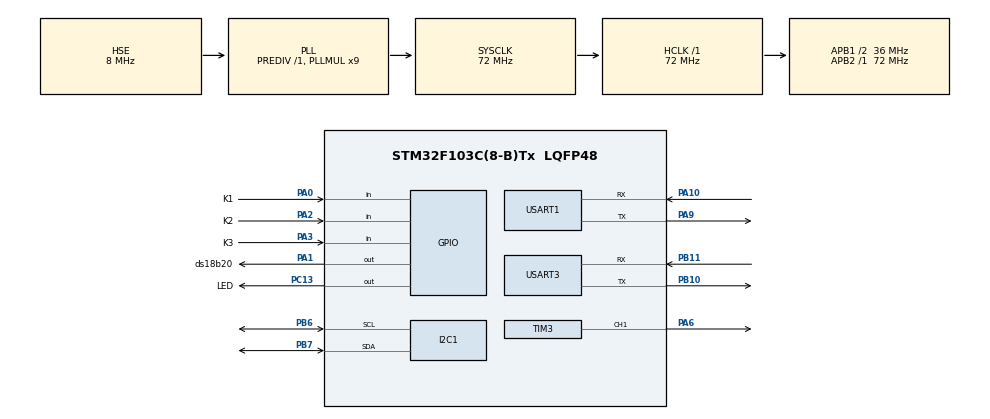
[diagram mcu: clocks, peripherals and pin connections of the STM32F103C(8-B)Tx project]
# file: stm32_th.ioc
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Mcu.Family=STM32F1
Mcu.Name=STM32F103C(8-B)Tx
Mcu.Package=LQFP48
NVIC.PriorityGroup=NVIC_PRIORITYGROUP_4
PA0-WKUP.GPIO_Label=K1
PA0-WKUP.GPIO_PuPd=GPIO_PULLUP
PA0-WKUP.Signal=GPIO_Input
PA1.GPIO_Label=ds18b20
PA1.Signal=GPIO_Output
PA10.Mode=Asynchronous
PA10.Signal=USART1_RX
PA13.Mode=Serial_Wire
PA13.Signal=SYS_JTMS-SWDIO
PA14.Mode=Serial_Wire
PA14.Signal=SYS_JTCK-SWCLK
PA2.GPIO_Label=K2
PA2.GPIO_PuPd=GPIO_PULLUP
PA2.Signal=GPIO_Input
PA3.GPIO_Label=K3
PA3.GPIO_PuPd=GPIO_PULLUP
PA3.Signal=GPIO_Input
PA6.Signal=S_TIM3_CH1
PA9.Mode=Asynchronous
PA9.Signal=USART1_TX
PB10.Mode=Asynchronous
PB10.Signal=USART3_TX
PB11.Mode=Asynchronous
PB11.Signal=USART3_RX
PB6.Mode=I2C
PB6.Signal=I2C1_SCL
PB7.Mode=I2C
PB7.Signal=I2C1_SDA
PC13-TAMPER-RTC.GPIO_Label=LED
PC13-TAMPER-RTC.Signal=GPIO_Output
PC14-OSC32_IN.Mode=LSE-External-Oscillator
PC14-OSC32_IN.Signal=RCC_OSC32_IN
PC15-OSC32_OUT.Mode=LSE-External-Oscillator
PC15-OSC32_OUT.Signal=RCC_OSC32_OUT
PD0-OSC_IN.Mode=HSE-External-Oscillator
PD0-OSC_IN.Signal=RCC_OSC_IN
PD1-OSC_OUT.Mode=HSE-External-Oscillator
PD1-OSC_OUT.Signal=RCC_OSC_OUT
ProjectManager.HeapSize=0x200
ProjectManager.StackSize=0x400
ProjectManager.TargetToolchain=STM32CubeIDE
RCC.AHBFreq_Value=72000000
RCC.APB1CLKDivider=RCC_HCLK_DIV2
RCC.APB1Freq_Value=36000000
RCC.APB1TimFreq_Value=72000000
RCC.APB2Freq_Value=72000000
RCC.APB2TimFreq_Value=72000000
RCC.HCLKFreq_Value=72000000
RCC.PLLMUL=RCC_PLL_MUL9
RCC.PLLSourceVirtual=RCC_PLLSOURCE_HSE
RCC.SYSCLKFreq_VALUE=72000000
RCC.SYSCLKSource=RCC_SYSCLKSOURCE_PLLCLK
RCC.USBFreq_Value=72000000
SH.S_TIM3_CH1.0=TIM3_CH1,PWM Generation1 CH1
TIM3.Channel-PWM\ Generation1\ CH1=TIM_CHANNEL_1
USART1.VirtualMode=VM_ASYNC
USART3.VirtualMode=VM_ASYNC
VP_TIM3_VS_ControllerModeClock.Mode=Clock Mode
board=custom

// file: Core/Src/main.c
/* USER CODE BEGIN Header */
/**
  ******************************************************************************
  * @file           : main.c
  * @brief          : Main program body
  ******************************************************************************
  * @attention
  *
  * Copyright (c) 2026 STMicroelectronics.
  * All rights reserved.
  *
  * This software is licensed under terms that can be found in the LICENSE file
  * in the root directory of this software component.
  * If no LICENSE file comes with this software, it is provided AS-IS.
  *
  ******************************************************************************
  */
/* USER CODE END Header */
#include "main.h"

/* USER CODE BEGIN Includes */
#include "scheduler.h"
#include "key.h"
#include "sensor.h"
#include "alarm.h"
#include "display.h"
#include "log.h"
#include "aht20.h"
#include "ens160.h"
/* USER CODE END Includes */

I2C_HandleTypeDef hi2c1;

TIM_HandleTypeDef htim3;

UART_HandleTypeDef huart1;
UART_HandleTypeDef huart3;

/* USER CODE BEGIN PV */
key_t g_keys[KEY_COUNT];
/* USER CODE END PV */

void SystemClock_Config(void);
static void MX_GPIO_Init(void);
static void MX_TIM3_Init(void);
static void MX_USART1_UART_Init(void);
static void MX_I2C1_Init(void);

/* USER CODE BEGIN 0 */
/* Task functions */
void Task_KeyScan(void)
{
    for (key_id_t i = 0; i < KEY_COUNT; i++) {
        Key_Scan10ms(&g_keys[i]);
        key_evt_t evt = Key_GetEvent(&g_keys[i]);
        if (evt != KEY_EVT_NONE) Menu_OnKey(i, evt);
    }
}
void Task_Display(void)
{
    sensor_data_t s = Sensor_GetData();
    Display_UpdateHistory(&s);
    Display_Refresh();
}
void Task_LED(void)        { HAL_GPIO_TogglePin(GPIOC, GPIO_PIN_13); }
void Task_Sensor(void)     { Sensor_TaskReadResult(); }
void Task_SensorStart(void) { Sensor_TaskStartConvert(); }
void Task_Alarm(void)      { Alarm_Task100ms(); Alarm_BuzzerTask100ms(); }
void Task_Log(void)        { Log_TaskReport(); }

task_t s_tasks[] = {
    { 0,   10,  Task_KeyScan     },
    { 0,   100, Task_Display    },
    { 0,   100, Task_Sensor     },
    { 0,   1000,Task_SensorStart },
    { 0,   100, Task_Alarm      },
    { 0,   500, Task_LED       },
    { 0,   2000,Task_Log       },
};
/* USER CODE END 0 */

int main(void)
{

  /* MCU Configuration--------------------------------------------------------*/

  /* Reset of all peripherals, Initializes the Flash interface and the Systick. */
  HAL_Init();

  /* Configure the system clock */
  SystemClock_Config();

  /* Initialize all configured peripherals */
  MX_GPIO_Init();
  MX_TIM3_Init();
  MX_USART1_UART_Init();
  MX_USART3_UART_Init();
  MX_I2C1_Init();
  /* USER CODE BEGIN 2 */
  CoreDebug->DEMCR |= CoreDebug_DEMCR_TRCENA_Msk;
  DWT->CYCCNT = 0;
  DWT->CTRL |= DWT_CTRL_CYCCNTENA_Msk;
  Sensor_Init();
  Alarm_Init();
  Display_Init();
  Key_Init(&g_keys[KEY_ID_K1], KEY_GPIO_Port, KEY_Pin,  GPIO_PIN_SET);
  Key_Init(&g_keys[KEY_ID_K2], K2_GPIO_Port, K2_Pin,  GPIO_PIN_SET);
  Key_Init(&g_keys[KEY_ID_K3], K3_GPIO_Port, K3_Pin,  GPIO_PIN_SET);
  Log_Init();
  /* USER CODE END 2 */

  /* Infinite loop */
  /* USER CODE BEGIN WHILE */
  while (1)
  {
    Scheduler_Run();
    /* USER CODE END WHILE */

  }
}

void SystemClock_Config(void)
{
  RCC_OscInitTypeDef RCC_OscInitStruct = {0};
  RCC_ClkInitTypeDef RCC_ClkInitStruct = {0};

  /** Initializes the RCC Oscillators according to the specified parameters
  * in the RCC_OscInitTypeDef structure.
  */
  RCC_OscInitStruct.OscillatorType = RCC_OSCILLATORTYPE_HSE;
  RCC_OscInitStruct.HSEState = RCC_HSE_ON;
  RCC_OscInitStruct.HSEPredivValue = RCC_HSE_PREDIV_DIV1;
  RCC_OscInitStruct.HSIState = RCC_HSI_ON;
  RCC_OscInitStruct.PLL.PLLState = RCC_PLL_ON;
  RCC_OscInitStruct.PLL.PLLSource = RCC_PLLSOURCE_HSE;
  RCC_OscInitStruct.PLL.PLLMUL = RCC_PLL_MUL9;
  if (HAL_RCC_OscConfig(&RCC_OscInitStruct) != HAL_OK)
  {
    Error_Handler();
  }

  /** Initializes the CPU, AHB and APB buses clocks
  */
  RCC_ClkInitStruct.ClockType = RCC_CLOCKTYPE_HCLK|RCC_CLOCKTYPE_SYSCLK
                              |RCC_CLOCKTYPE_PCLK1|RCC_CLOCKTYPE_PCLK2;
  RCC_ClkInitStruct.SYSCLKSource = RCC_SYSCLKSOURCE_PLLCLK;
  RCC_ClkInitStruct.AHBCLKDivider = RCC_SYSCLK_DIV1;
  RCC_ClkInitStruct.APB1CLKDivider = RCC_HCLK_DIV2;
  RCC_ClkInitStruct.APB2CLKDivider = RCC_HCLK_DIV1;

  if (HAL_RCC_ClockConfig(&RCC_ClkInitStruct, FLASH_LATENCY_2) != HAL_OK)
  {
    Error_Handler();
  }
}

static void MX_I2C1_Init(void)
{

  hi2c1.Instance = I2C1;
  hi2c1.Init.ClockSpeed = 100000;
  hi2c1.Init.DutyCycle = I2C_DUTYCYCLE_2;
  hi2c1.Init.OwnAddress1 = 0;
  hi2c1.Init.AddressingMode = I2C_ADDRESSINGMODE_7BIT;
  hi2c1.Init.DualAddressMode = I2C_DUALADDRESS_DISABLE;
  hi2c1.Init.OwnAddress2 = 0;
  hi2c1.Init.GeneralCallMode = I2C_GENERALCALL_DISABLE;
  hi2c1.Init.NoStretchMode = I2C_NOSTRETCH_DISABLE;
  if (HAL_I2C_Init(&hi2c1) != HAL_OK)
  {
    Error_Handler();
  }

}

static void MX_TIM3_Init(void)
{

  TIM_MasterConfigTypeDef sMasterConfig = {0};
  TIM_OC_InitTypeDef sConfigOC = {0};

  htim3.Instance = TIM3;
  htim3.Init.Prescaler = 0;
  htim3.Init.CounterMode = TIM_COUNTERMODE_UP;
  htim3.Init.Period = 65535;
  htim3.Init.ClockDivision = TIM_CLOCKDIVISION_DIV1;
  htim3.Init.AutoReloadPreload = TIM_AUTORELOAD_PRELOAD_DISABLE;
  if (HAL_TIM_PWM_Init(&htim3) != HAL_OK)
  {
    Error_Handler();
  }
  sMasterConfig.MasterOutputTrigger = TIM_TRGO_RESET;
  sMasterConfig.MasterSlaveMode = TIM_MASTERSLAVEMODE_DISABLE;
  if (HAL_TIMEx_MasterConfigSynchronization(&htim3, &sMasterConfig) != HAL_OK)
  {
    Error_Handler();
  }
  sConfigOC.OCMode = TIM_OCMODE_PWM1;
  sConfigOC.Pulse = 0;
  sConfigOC.OCPolarity = TIM_OCPOLARITY_HIGH;
  sConfigOC.OCFastMode = TIM_OCFAST_DISABLE;
  if (HAL_TIM_PWM_ConfigChannel(&htim3, &sConfigOC, TIM_CHANNEL_1) != HAL_OK)
  {
    Error_Handler();
  }
  HAL_TIM_MspPostInit(&htim3);

}

static void MX_USART1_UART_Init(void)
{

  huart1.Instance = USART1;
  huart1.Init.BaudRate = 115200;
  huart1.Init.WordLength = UART_WORDLENGTH_8B;
  huart1.Init.StopBits = UART_STOPBITS_1;
  huart1.Init.Parity = UART_PARITY_NONE;
  huart1.Init.Mode = UART_MODE_TX_RX;
  huart1.Init.HwFlowCtl = UART_HWCONTROL_NONE;
  huart1.Init.OverSampling = UART_OVERSAMPLING_16;
  if (HAL_UART_Init(&huart1) != HAL_OK)
  {
    Error_Handler();
  }

}

void MX_USART3_UART_Init(void)
{

  huart3.Instance = USART3;
  huart3.Init.BaudRate = 115200;
  huart3.Init.WordLength = UART_WORDLENGTH_8B;
  huart3.Init.StopBits = UART_STOPBITS_1;
  huart3.Init.Parity = UART_PARITY_NONE;
  huart3.Init.Mode = UART_MODE_TX_RX;
  huart3.Init.HwFlowCtl = UART_HWCONTROL_NONE;
  huart3.Init.OverSampling = UART_OVERSAMPLING_16;
  if (HAL_UART_Init(&huart3) != HAL_OK)
  {
    Error_Handler();
  }

}

static void MX_GPIO_Init(void)
{
  GPIO_InitTypeDef GPIO_InitStruct = {0};

  /* GPIO Ports Clock Enable */
  __HAL_RCC_GPIOC_CLK_ENABLE();
  __HAL_RCC_GPIOD_CLK_ENABLE();
  __HAL_RCC_GPIOA_CLK_ENABLE();
  __HAL_RCC_GPIOB_CLK_ENABLE();

  /*Configure GPIO pin Output Level */
  HAL_GPIO_WritePin(LED_GPIO_Port, LED_Pin, GPIO_PIN_RESET);

  /*Configure GPIO pin Output Level */
  HAL_GPIO_WritePin(ds18b20_GPIO_Port, ds18b20_Pin, GPIO_PIN_RESET);

  /*Configure GPIO pin : LED_Pin */
  GPIO_InitStruct.Pin = LED_Pin;
  GPIO_InitStruct.Mode = GPIO_MODE_OUTPUT_PP;
  GPIO_InitStruct.Pull = GPIO_NOPULL;
  GPIO_InitStruct.Speed = GPIO_SPEED_FREQ_LOW;
  HAL_GPIO_Init(LED_GPIO_Port, &GPIO_InitStruct);

  /*Configure GPIO pins : PA0=K1, PA2=K2, PA3=K3 */
  GPIO_InitStruct.Pin = KEY_Pin | K2_Pin | K3_Pin;
  GPIO_InitStruct.Mode = GPIO_MODE_INPUT;
  GPIO_InitStruct.Pull = GPIO_PULLDOWN;
  HAL_GPIO_Init(GPIOA, &GPIO_InitStruct);

  /*Configure GPIO pin : ds18b20_Pin */
  GPIO_InitStruct.Pin = ds18b20_Pin;
  GPIO_InitStruct.Mode = GPIO_MODE_OUTPUT_PP;
  GPIO_InitStruct.Pull = GPIO_NOPULL;
  GPIO_InitStruct.Speed = GPIO_SPEED_FREQ_LOW;
  HAL_GPIO_Init(ds18b20_GPIO_Port, &GPIO_InitStruct);

}

void Error_Handler(void)
{
  __disable_irq();
  while (1)
  {
  }
}
